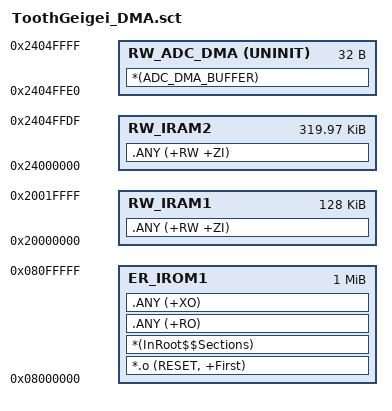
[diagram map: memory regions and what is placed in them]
; Dedicated DMA-safe ADC1 storage for STM32H723.
; DMA1 cannot access DTCM (0x20000000). The ADC buffer is therefore pinned to
; one exclusive, 32-byte-aligned cache line at the end of AXI SRAM.

LR_IROM1 0x08000000 0x00100000  {
  ER_IROM1 0x08000000 0x00100000  {
   *.o (RESET, +First)
   *(InRoot$$Sections)
   .ANY (+RO)
   .ANY (+XO)
  }
  RW_IRAM1 0x20000000 0x00020000  {
   .ANY (+RW +ZI)
  }
  RW_IRAM2 0x24000000 0x0004FFE0  {
   .ANY (+RW +ZI)
  }
  RW_ADC_DMA 0x2404FFE0 UNINIT 0x00000020  {
   *(ADC_DMA_BUFFER)
  }
}

